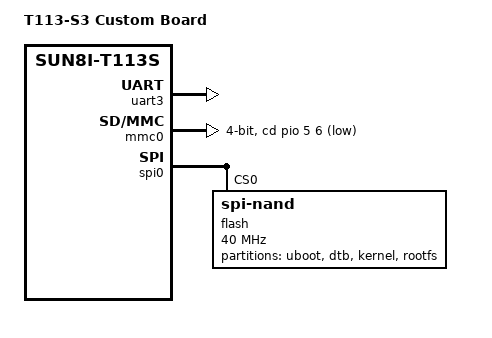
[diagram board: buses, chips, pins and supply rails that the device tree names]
// ============================================================
// T113-S3 板级 DTS 模板 —— 按实际硬件修改
//
// 使用方法: config/board.env 中 KERNEL_DTS=board 后运行 make kernel
//
// T113-S3 (SiP 封装, 内置 128M DDR3): PB8/PB9 被 SiP 内部占用,
// 调试串口为 UART3 @ PB6(TX)/PB7(RX) -> console=ttyS3
//
// 引脚速查 (sunxi-d1s-t113.dtsi):
//   spi0  : PC2~PC5           (spi0_pins)
//   uart3 : PB6/PB7           (uart3_pb_pins)
//   mmc0  : 默认 mmc0_pins, 卡检测 PF6
// ============================================================
/dts-v1/;
#include "sun8i-t113s.dtsi"
#include <dt-bindings/gpio/gpio.h>

/ {
	model = "T113-S3 Custom Board";
	compatible = "vendor,t113-s3-board", "allwinner,sun8i-t113s", "allwinner,sun8i";

	aliases {
		serial3 = &uart3;
	};

	chosen {
		stdout-path = "serial3:115200n8";
	};

	/* 按需添加: gpio-leds, gpio-keys, regulators ... */
};

/* 调试串口: UART3 @ PB6(TX)/PB7(RX) */
&uart3 {
	pinctrl-names = "default";
	pinctrl-0 = <&uart3_pb_pins>;
	status = "okay";
};

/* TF 卡槽 */
&mmc0 {
	pinctrl-names = "default";
	pinctrl-0 = <&mmc0_pins>;
	bus-width = <4>;
	cd-gpios = <&pio 5 6 GPIO_ACTIVE_LOW>; /* PF6, 按板子修改 */
	disable-wp;
	status = "okay";
};

/* ============================================================
 * SPI flash: Winbond W25N02KVZEIR (SPI NAND, 2Gbit / 256MB)
 *   页 2048B + OOB 128B, 擦除块 128KB -> 分区必须按 128KB 对齐
 *   分区表必须与 config/board.env 的 SPI_*_SIZE 一致,
 *   scripts/pack-spi.sh 打包前会逐项校验 (不一致直接报错)
 *   分区顺序 = mtd0..mtd3, rootfs 是第 4 个 -> root=/dev/mtdblock3
 *
 *   换回 SPI NOR 板: 用下面注释里的 jedec,spi-nor 节点替换 spi-nand 节点,
 *   并把 config/board.env 的 SPI_FLASH_TYPE 改成 nor (布局也随之变化)
 * ============================================================ */
&spi0 {
	pinctrl-names = "default";
	pinctrl-0 = <&spi0_pins>;
	status = "okay";

	flash@0 {
		compatible = "spi-nand";
		reg = <0>;
		spi-max-frequency = <40000000>;
		#address-cells = <1>;
		#size-cells = <1>;

		partitions {
			compatible = "fixed-partitions";
			#address-cells = <1>;
			#size-cells = <1>;

			partition@0 {
				label = "uboot";
				reg = <0x0000000 0x0100000>;
			};

			partition@100000 {
				label = "dtb";
				reg = <0x0100000 0x0040000>;
			};

			partition@140000 {
				label = "kernel";
				reg = <0x0140000 0x1000000>;
			};

			partition@1140000 {
				label = "rootfs";
				reg = <0x1140000 0x0eec0000>;
			};
		};
	};

	/* SPI NOR 板 (16/32MB, 布局见 SPI_FLASH_TYPE=nor):
	 * flash@0 {
	 *	compatible = "jedec,spi-nor";
	 *	reg = <0>;
	 *	spi-max-frequency = <40000000>;
	 * };
	 */
};

/* 千兆以太网 (RMII/RGMII 视 PHY 而定) */
/*
&emac {
	status = "okay";
	phy-mode = "rmii";
	fixed-link {
		speed = <100>;
		full-duplex;
	};
};
*/

/* USB OTG */
/*
&usb_otg {
	status = "okay";
	dr_mode = "otg";
};
*/
